# YTM32B1HA0 register map
Vendor: YTMicro; File version: 1.0
CPU: little endian, MPU, FPU, 2 interrupt priority bits
Registers are 32-bit, read-write, reset 0x0 unless marked. A register's access mark holds for its fields unless they carry their own. Offsets are from the block's base; [hi:lo] are bit positions; {n}, {i} and the like mark numbered series; 'fields as' and 'values as' point back to an identical list.

## ENET (part 7 of 10) — Ethernet Quality-of-Service
Base 0x401E4000; register names take the prefix ENET_
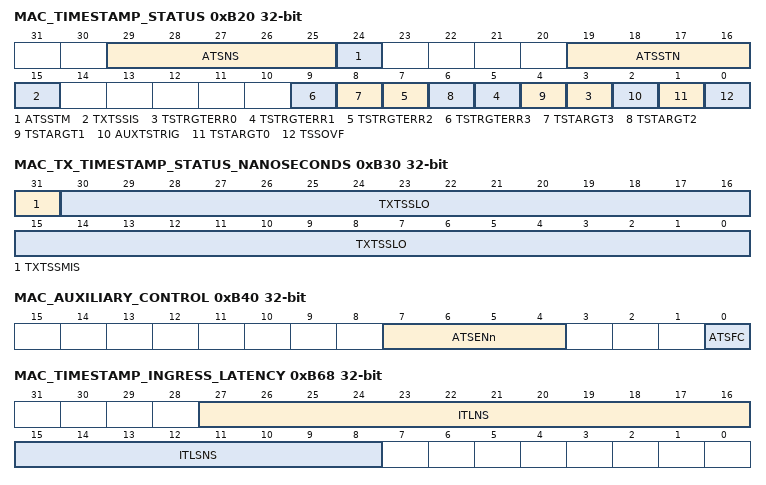
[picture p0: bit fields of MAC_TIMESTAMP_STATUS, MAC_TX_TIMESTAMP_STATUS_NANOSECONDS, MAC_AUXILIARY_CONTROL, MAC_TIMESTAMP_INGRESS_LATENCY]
0xB20 MAC_TIMESTAMP_STATUS ro — Timestamp Status register. All bits except Bits[27:25] gets cleared when the application reads this register.
  [29:25] ATSNS rw — This field indicates the number of Snapshots available in the FIFO. A value equal to the selected depth of FIFO (4, 8, or 16) indicates that the Auxiliary Snapshot FIFO is full. These bits are cleared (to 00000) when the Auxiliary snapshot FIFO clear bit is set. This bit is valid only if the Add IEEE 1588 Auxiliary Snapshot option is selected.
  [24] ATSSTM rw — This bit is set when the Auxiliary timestamp snapshot FIFO is full and external trigger was set. This indicates that the latest snapshot is not stored in the FIFO. This bit is valid only if the Add IEEE 1588 Auxiliary Snapshot option is selected.
    0=Auxiliary Timestamp Snapshot Trigger Missed status not detected; 1=Auxiliary Timestamp Snapshot Trigger Missed status detected
  [19:16] ATSSTN rw — These bits identify the Auxiliary trigger inputs for which the timestamp available in the Auxiliary Snapshot Register is applicable. When more than one bit is set at the same time, it means that corresponding auxiliary triggers were sampled at the same clock. These bits are applicable only if the number of Auxiliary snapshots is more than one. One bit is assigned for each trigger as shown in the following list: ■ Bit 16: Auxiliary trigger 0 ■ Bit 17: Auxiliary trigger 1 ■ Bit 18: Auxiliary trigger 2 ■ Bit 19: Auxiliary trigger 3 The software can read this register to find the triggers that are set when the timestamp is taken. Access restriction applies. Clears on read. Self-set to 1 on internal event.
  [15] TXTSSIS rw — In non-EQOS_CORE configurations when drop transmit status is enabled in MTL, this bit is set when the captured transmit timestamp is updated in the MAC_Tx_Timestamp_Status_Nanoseconds and MAC_Tx_Timestamp_Status_Seconds registers. When PTP offload feature is enabled, this bit is set when the captured transmit timestamp is updated in the MAC_Tx_Timestamp_Status_Nanoseconds and MAC_Tx_Timestamp_Status_Seconds registers, for PTO generated Delay Request and Pdelay request packets. This bit is cleared when the MAC_Tx_Timestamp_Status_Seconds register is read (or write to MAC_Tx_Timestamp_Status_Seconds register when RCWE bit of MAC_CSR_SW_Ctrl register is set).
    0=Tx Timestamp Status Interrupt status not detected; 1=Tx Timestamp Status Interrupt status detected
  [2n+3] TSTRGTERR{n} rw (n=0..3) — This bit is set when the latest target time programmed in the MAC_PPS{n}_Target_Time_Seconds and MAC_PPS{n}_Target_Time_Nanoseconds registers elapses. This bit is cleared when the application reads this bit. Access restriction applies. Clears on read (or this bit is written to 1 when RCWE bit in MAC_CSR_SW_Ctrl register is set). Self-set to 1 on internal event.
    0=Timestamp Target Time Error status not detected; 1=Timestamp Target Time Error status detected
  [8] TSTARGT3 rw — When this bit is set, it indicates that the value of system time is greater than or equal to the value specified in the MAC_PPS3_Target_Time_Seconds and MAC_PPS3_Target_Time_Nanoseconds registers. Access restriction applies. Clears on read (or this bit is written to 1 when RCWE bit in MAC_CSR_SW_Ctrl register is set). Self-set to 1 on internal event.
    0=Timestamp Target Time Reached for Target Time PPS3 status not detected; 1=Timestamp Target Time Reached for Target Time PPS3 status detected
  [6] TSTARGT2 rw — When this bit is set, it indicates that the value of system time is greater than or equal to the value specified in the MAC_PPS2_Target_Time_Seconds and MAC_PPS2_Target_Time_Nanoseconds registers. Access restriction applies. Clears on read (or this bit is written to 1 when RCWE bit in MAC_CSR_SW_Ctrl register is set). Self-set to 1 on internal event.
    0=Timestamp Target Time Reached for Target Time PPS2 status not detected; 1=Timestamp Target Time Reached for Target Time PPS2 status detected
  [4] TSTARGT1 rw — When this bit is set, it indicates that the value of system time is greater than or equal to the value specified in the MAC_PPS1_Target_Time_Seconds and MAC_PPS1_Target_Time_Nanoseconds registers. Access restriction applies. Clears on read (or this bit is written to 1 when RCWE bit in MAC_CSR_SW_Ctrl register is set). Self-set to 1 on internal event.
    0=Timestamp Target Time Reached for Target Time PPS1 status not detected; 1=Timestamp Target Time Reached for Target Time PPS1 status detected
  [2] AUXTSTRIG rw — This bit is set high when the auxiliary snapshot is written to the FIFO. This bit is valid only if the Add IEEE 1588 Auxiliary Snapshot option is selected. Access restriction applies. Clears on read (or this bit is written to 1 when RCWE bit in MAC_CSR_SW_Ctrl register is set). Self-set to 1 on internal event.
    0=Auxiliary Timestamp Trigger Snapshot status not detected; 1=Auxiliary Timestamp Trigger Snapshot status detected
  [1] TSTARGT0 rw — When set, this bit indicates that the value of system time is greater than or equal to the value specified in the MAC_PPS0_Target_Time_Seconds and MAC_PPS0_Target_Time_Nanoseconds registers. Access restriction applies. Clears on read (or this bit is written to 1 when RCWE bit in MAC_CSR_SW_Ctrl register is set). Self-set to 1 on internal event.
    0=Timestamp Target Time Reached status not detected; 1=Timestamp Target Time Reached status detected
  [0] TSSOVF rw — When this bit is set, it indicates that the seconds value of the timestamp (when supporting version 2 format) has overflowed beyond 32'hFFFF_FFFF. Access restriction applies. Clears on read (or this bit is written to 1 when RCWE bit in MAC_CSR_SW_Ctrl register is set). Self-set to 1 on internal event.
    0=Timestamp Seconds Overflow status not detected; 1=Ti
0xB30 MAC_TX_TIMESTAMP_STATUS_NANOSECONDS — This register contains the nanosecond part of timestamp captured for Transmit packets when Tx status is disabled. The MAC_Tx_Timestamp_Status_Nanoseconds register, along with MAC_Tx_Timestamp_Sta- tus_Seconds, gives the 64-bit timestamp captured for the PTP packet successfully transmitted by the MAC. This value is considered to be read by the application when the last byte of MAC_Tx_Time- stamp_Status_Nanoseconds is read. In the little-endian mode, this means when bits[31:24] are read; in big-endian mode, bits[7:0] are read. If the application does not read these registers and timestamp of another packet is captured, then either the current timestamp is lost (overwritten) or the new timestamp is lost (dropped), depending on the setting of the TXTSSTSM bit of the MAC_Timestamp_Control register. The status bit TXTSC bit [15] in MAC_Timestamp_Status register is set whenever the MAC transmitter captures the timestamp.
  [31] TXTSSMIS — When this bit is set, it indicates one of the following: ■ The timestamp of the current packet is ignored if TXTSSTSM bit of the MAC_Timestamp_Control register is reset ■ The timestamp of the previous packet is overwritten with timestamp of the current packet if TXTSSTSM bit of the MAC_Timestamp_Control register is set. Access restriction applies. Clears on read. Self-set to 1 on internal event.
    0=Transmit Timestamp Status Missed status not detected; 1=Transmit Timestamp Status Missed status detected
  [30:0] TXTSSLO — This field contains the 31 bits of the Nanoseconds field of the Transmit packet's captured timestamp.
0xB34 MAC_TX_TIMESTAMP_STATUS_SECONDS — The register contains the higher 32 bits of the timestamp (in seconds) captured when a PTP packet is transmitted.
  [31:0] TXTSSHI — This field contains the lower 32 bits of the Seconds field of Transmit packet's captured timestamp.
0xB40 MAC_AUXILIARY_CONTROL — The Auxiliary Timestamp Control register controls the Auxiliary Timestamp snapshot.
  [7:4] ATSENn — This bit controls the capturing of Auxiliary Snapshot Trigger n. When this bit is set, the auxiliary snapshot of the event on ptp_aux_trig_i[n] input is enabled. When this bit is reset, the events on this input are ignored.
    0=Auxiliary Snapshot n is disabled; 1=Auxiliary Snapshot n is enabled
  [0] ATSFC — When set, this bit resets the pointers of the Auxiliary Snapshot FIFO. This bit is cleared when the pointers are reset and the FIFO is empty. When this bit is high, the auxiliary snapshots are stored in the FIFO. Access restriction applies. Setting 1 sets. Self-cleared. Setting 0 has no effect.
    0=Auxiliary Snapshot FIFO Clear is disabled; 1=Auxiliary Snapshot FIFO Clear is enabled
0xB48 MAC_AUXILIARY_TIMESTAMP_NANOSECONDS — The Auxiliary Timestamp Nanoseconds register, along with MAC_Auxiliary_Time- stamp_Seconds, gives the 64-bit timestamp stored as auxiliary snapshot. These two registers form the read port of a 64-bit wide FIFO with a depth of 4, 8, or 16 as selected while configuring the core. You can store multiple snapshots in this FIFO. Bits[29:25] in MAC_Timestamp_Status indicate the fill-level of the FIFO. The top of the FIFO is removed only when the last byte of MAC_Auxiliary_Time- stamp_Seconds register is read. In the little-endian mode, this means when Bits[31:24] are read and in big-endian mode, Bits[7:0] are read.
  [30:0] AUXTSLO — Contains the lower 31 bits (nanoseconds field) of the auxiliary timestamp.
0xB4C MAC_AUXILIARY_TIMESTAMP_SECONDS — The Auxiliary Timestamp - Seconds register contains the lower 32 bits of the Seconds field of the auxiliary timestamp register.
  [31:0] AUXTSHI — Contains the lower 32 bits of the Seconds field of the auxiliary timestamp.
0xB50 MAC_TIMESTAMP_INGRESS_ASYM_CORR — The MAC Timestamp Ingress Asymmetry Correction register contains the Ingress Asymmetry Correction value to be used while updating correction field in PDelay_Resp PTP messages.
  [31:0] OSTIAC — This field contains the ingress path asymmetry value to be added to correctionField of Pdelay_Resp PTP packet. The programmed value should be in units of nanoseconds and multiplied by 2^16. For example, 2.5 ns is represented as 0x00028000. The value can also be negative, which is represented in 2's complement form with bit 31 representing the sign bit.
0xB54 MAC_TIMESTAMP_EGRESS_ASYM_CORR — The MAC Timestamp Egress Asymmetry Correction register contains the Egress Asym- metry Correction value to be used while updating the correction field in PDelay_Req PTP messages.
  [31:0] OSTEAC — This field contains the egress path asymmetry value to be subtracted from correctionField of Pdelay_Resp PTP packet. The programmed value must be the negated value in units of nanoseconds multiplied by 2^16. For example, if the required correction is +2.5 ns, the programmed value must be 0xFFFD_8000, which is the 2's complement of 0x0002_8000(2.5 * 216). Similarly, if the required correction is -3.3 ns, the programmed value is 0x0003_4CCC (3.3 * 216).
0xB58 MAC_TIMESTAMP_INGRESS_CORR_NANOSECOND — This register contains the correction value in nanoseconds to be used with the captured timestamp value in the ingress path.
  [31:0] TSIC — This field contains the ingress path correction value as defined by the Ingress Correction expression.
0xB5C MAC_TIMESTAMP_EGRESS_CORR_NANOSECOND — This register contains the correction value in nanoseconds to be used with the captured timestamp value in the egress path.
  [31:0] TSEC — This field contains the nanoseconds part of the egress path correction value as defined by the Egress Correction expression.
0xB60 MAC_TIMESTAMP_INGRESS_CORR_SUBNANOSEC — This register contains the sub-nanosecond part of the correction value to be used with the captured timestamp value, for ingress direction.
  [15:8] TSICSNS — This field contains the sub-nanoseconds part of the ingress path correction value as defined by the "Ingress Correction" expression.
0xB64 MAC_TIMESTAMP_EGRESS_CORR_SUBNANOSEC — This register contains the sub-nanosecond part of the correction value to be used with the captured timestamp value, for egress direction.
  [15:8] TSECSNS — This field contains the sub-nanoseconds part of the egress path correction value as defined by the "Egress Correction" expression.
0xB68 MAC_TIMESTAMP_INGRESS_LATENCY ro — This register holds the Ingress MAC latency.
  [27:16] ITLNS rw — This register holds the average latency in sub-nanoseconds between the input ports (phy_rxd_i) of MAC and the actual point (GMII/MII) where the ingress timestamp is taken. Ingress correction value is computed as described in the section 7.1.2.4.1 of QoS Databook.
  [15:8] ITLSNS rw — This register holds the average latency in nanoseconds between the input ports (phy_rxd_i) of MAC and the actual point (GMII/MII) where the ingress timestamp is taken. Ingress correction value is computed as described in the section 7.1.2.4.1 of QoS Databook.
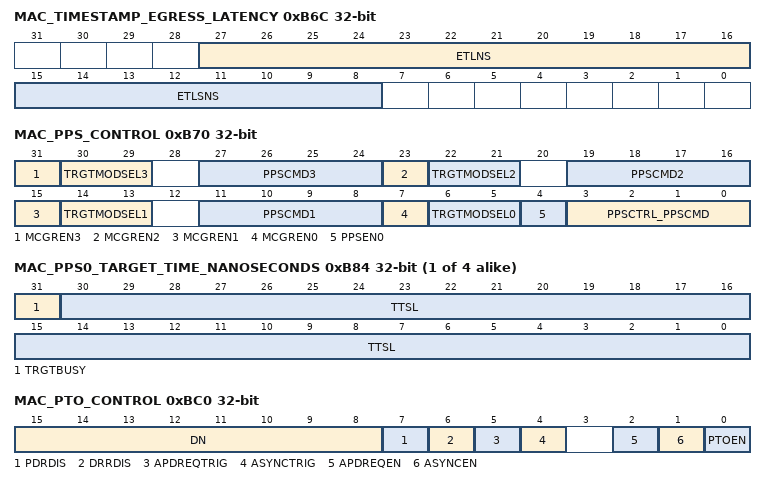
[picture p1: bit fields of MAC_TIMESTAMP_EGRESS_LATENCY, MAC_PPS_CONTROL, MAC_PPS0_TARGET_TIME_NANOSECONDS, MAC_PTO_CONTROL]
0xB6C MAC_TIMESTAMP_EGRESS_LATENCY ro — This register holds the Egress MAC latency.
  [27:16] ETLNS rw — This register holds the average latency in nanoseconds between the actual point (GMII/MII) where the egress timestamp is taken and the output ports (phy_txd_o) of the MAC. Ingress correction value is computed as described in the section 7.1.2.4.2 of QoS Databook.
  [15:8] ETLSNS rw — This register holds the average latency in sub-nanoseconds between the actual point (GMII/MII) where the egress timestamp is taken and the output ports (phy_txd_o) of the MAC. Ingress correction value is computed as described in the section 7.1.2.4.2 of QoS Databook.
0xB70 MAC_PPS_CONTROL — Bits[30:24] of this register are valid only when four Flexible PPS outputs are selected. Bits[22:16] are valid only when three or more Flexible PPS outputs are selected. Bits[14:8] are valid only when two or more Flexible PPS outputs are selected. Bits[6:4] are valid only when Flexible PPS feature is selected.
  [31] MCGREN3 — This field enables the 3rd PPS instance to operate in PPS or MCGR mode. When set it operates in MCGR mode and on reset it operates in PPS mode.
  [8n+6:8n+5] TRGTMODSEL{n} (n=0..3) — This field indicates the Target Time registers (MAC_PPS{n}_Target_Time_Seconds and MAC_PPS{n}_Target_Time_Nanoseconds) mode for PPS{n} output signal.
    0=Target Time registers are programmed only for generating the interrupt event. The Flexible PPS function must not be enabled in this mode, otherwise spurious transitions may be observed on the corre- sponding ptp_pps_o output port; 2=Target Time registers are programmed for generating the interrupt event and starting or stopping the PPS0 output signal generation; 3=Target Time registers are programmed only for starting or stopping the PPS0 output signal gener- ation. No interrupt is asserted
  [27:24] PPSCMD3 — This field controls the flexible PPS3 output (ptp_pps_o[3]) signal. This field is similar to the PPSCMD0[2:0] field. If MCGREN3 is set, then PPSCMD3 indicated by these 4 bits [27:24] are taken as Presentation Time Control bits for media clock generation and recovery for comparator instance 3. This field is similar to the PPSCMD0 Presentation Time Control bits. If MCGREN3 is not set then only 3 bits from [26:24] is used as PPSCMD3 and the 4th bit is to be set as 0. Access restriction applies. Setting 1 sets. Self-cleared. Setting 0 has no effect.
  [23] MCGREN2 — This field enables the 2nd PPS instance to operate in PPS or MCGR mode. When set it operates in MCGR mode and on reset it operates in PPS mode.
    0=2nd PPS instance is disabled to operate in PPS or MCGR mode; 1=2nd PPS instance is enabled to operate in PPS or MCGR mode
  [19:16] PPSCMD2 — This field controls the flexible PPS2 output (ptp_pps_o[2]) signal. This field is similar to the PPSCMD0[2:0] field. If MCGREN2 is set, then PPSCMD2 indicated by these 4 bits [19:16] are taken as Presentation Time Control bits for media clock generation and recovery for comparator instance 2. This field is similar to the PPSCMD0 Presentation Time Control bits. If MCGREN2 is not set then only 3 bits from [18:16] is used as PPSCMD2 and the 4th bit is to be set as 0. Access restriction applies. Setting 1 sets. Self-cleared. Setting 0 has no effect.
  [15] MCGREN1 — This field enables the 1st PPS instance to operate in PPS or MCGR mode. When set it operates in MCGR mode and on reset it operates in PPS mode.
    0=1st PPS instance is disabled to operate in PPS or MCGR mode; 1=1st PPS instance is enabled to operate in PPS or MCGR mode
  [11:8] PPSCMD1 — This field controls the flexible PPS1 output (ptp_pps_o[1]) signal. This field is similar to the PPSCMD0[2:0] field. If MCGREN1 is set, then PPSCMD1 indicated by these 4 bits [11:8] are taken as Presentation Time Control bits for media clock generation and recovery for comparator instance 1. This field is similar to the PPSCMD0 Presentation Time Control bits. If MCGREN1 is not set then only 3 bits from [10:8] is used as PPSCMD1 and the 4th bit is to be set as 0. Access restriction applies. Setting 1 sets. Self-cleared. Setting 0 has no effect.
  [7] MCGREN0 — This field enables the 0th PPS instance to operate in PPS or MCGR mode. When set it operates in MCGR mode and on reset it operates in PPS mode.
    0=0th PPS instance is disabled to operate in PPS or MCGR mode; 1=0th PPS instance is enabled to operate in PPS or MCGR mode
  [4] PPSEN0 — When this bit is set, Bits[3:0] function as PPSCMD. When this bit is reset, Bits[3:0] function as PPSCTRL (Fixed PPS mode).
    0=Flexible PPS Output Mode is disabled; 1=Flexible PPS Output Mode is enabled
  [3:0] PPSCTRL_PPSCMD — // TODO This field controls the frequency of the PPS0 output (ptp_pps_o[0]) signal. The default value of PPSCTRL is 0000, and the PPS output is 1 pulse (of width clk_ptp_i) every second. For other values of PPSCTRL, the PPS output becomes a generated clock of following frequencies: ■ 0001: The binary rollover is 2 Hz, and the digital rollover is 1 Hz. ■ 0010: The binary rollover is 4 Hz, and the digital rollover is 2 Hz. ■ 0011: The binary rollover is 8 Hz, and the digital rollover is 4 Hz. ■ 0100: The binary rollover is 16 Hz, and the digital rollover is 8 Hz. ■ .. ■ 1111: The binary rollover is 32.768 KHz and the digital roll- over is 16.384 KHz. Note: In the binary rollover mode, the PPS output (ptp_pps_o) has a duty cycle of 50 percent with these frequencies. In the digital rollover mode, the PPS output frequency is an average number. The actual clock is of different frequency that gets synchronized every second. For example: ■ When PPSCTRL = 0001, the PPS (1 Hz) has a low period of 537 ms and a high period of 463 ms ■ When PPSCTRL = 0010, the PPS (2 Hz) is a sequence of One clock of 50 percent duty cycle and 537 ms period Second clock of 463 ms period (268 ms low and 195 ms high) ■ When PPSCTRL = 0011, the PPS (4 Hz) is a sequence of Three clocks of 50 percent duty cycle and 268 ms period Fourth clock of 195 ms period (134 ms low and 61 ms high) This behavior is because of the non-linear toggling of bits in the digital rollover mode in the MAC_System_Time_Nanoseconds register. or Flexible PPS Output (ptp_pps_o[0]) Control Programming these bits with a non-zero value instructs the MAC to initiate an event. When the command is transferred or synchronized to the PTP clock domain, these bits get cleared automatically. The software should ensure that these bits are programmed only when they are 'all-zero'. The following list describes the values of PPSCMD0: ■ 0000: No Command ■ 0001: START Single Pulse This command generates single pulse rising at the start point defined in MAC_PPS0_Target_Time_Seconds and MAC_PPS0_Target_Time_Nanoseconds register and of a duration defined in the PPS0 Width Register. ■ 0010: START Pulse Train This command generates the train of pulses rising at the start point defined in the Target Time Registers and of a duration defined in the PPS0 Width Register and repeated at interval defined in the PPS Interval Register. By default, the PPS pulse train is free-running unless stopped by the 'Stop Pulse train at time' or 'Stop Pulse Train immediately' commands. ■ 0011: Cancel START This command cancels the START Single Pulse and START Pulse Train commands if the system time has not crossed the programmed start time. ■ 0100: STOP Pulse train at time This command stops the train of pulses initiated by the START Pulse Train command (PPSCMD = 0010) after the time programmed in the Target Time registers elapses. ■ 0101: STOP Pulse Train immediately This command immediately stops the train of pulses initiated by the START Pulse Train command (PPSCMD = 0010). ■ 110: Cancel STOP Pulse train This command cancels the STOP pulse train at time command if the programmed stop time has not elapsed. The PPS pulse train becomes free-running on the successful execution of this command. ■ 0111-1111: Reserved or Presentation Time Control If MCGREN0 is set then these bits are treated as Presentation time control bits. The following list describes the values of PPSCMD0: ■ 0000: No Operation related to MCGR will be carried out. If set to this value in the mid of clock recovery or generation all the processing inputs will be flushed. ■ 0001: Capture the Presentation time at rising edge of mcg_pst_trig_i[0] into the MAC_PPS0_Target_Time_Sec- onds register ■ 0010: Capture the Presentation time at falling edge of mcg_pst_trig_i[0] into the MAC_PPS0_Target_Time_Sec- onds register ■ 0011: Capture the Presentation time at both edges of mcg_pst_trig_i[0] into the MAC_PPS0_Target_Time_Sec- onds register ■ 0100-1000: Reserved ■ 1001: Toggle output on compare ■ 1010: Pulse output low on compare for one PTP-clock cycle ■ 1011: Pulse output high on compare for one PTP-clock cycle ■ 1100-1111: Reserved
{0xB80+0x10*i} MAC_PPS{i}_TARGET_TIME_SECONDS (i=0..3) — The PPS Target Time Seconds register, along with PPS Target Time Nanoseconds register, is used to schedule an interrupt event [Bit 1 of MAC_Timestamp_Status] when the system time exceeds the value programmed in these registers.
  [31:0] TSTRH — This field stores the time in seconds. When the timestamp value matches or exceeds both Target Timestamp registers, the MAC starts or stops the PPS signal output and generates an interrupt (if enabled) based on Target Time mode selected for the corresponding PPS output in the MAC_PPS_Control register. If DWC_EQOS_FLEXI_PPS_OUT_EN is enabled in the configuration and PTGE field of MAC_Timestamp_Control Register is set with Presentation time control set in recovery mode, then these bits indicate the TPT being programmed by the application and in generation mode it indicates the CPT generated at the sampled trigger.
{0xB84+0x10*i} MAC_PPS{i}_TARGET_TIME_NANOSECONDS (i=0..3) — PPSn Target Time Nanoseconds register.
  [31] TRGTBUSY — The MAC sets this bit when the PPSCMDn field in the MAC_PPS_Control register is programmed to 010 or 011. Programming the PPSCMDn field to 010 or 011 instructs the MAC to synchronize the Target Time Registers to the PTP clock domain. The MAC clears this bit after synchronizing the Target Time Registers to the PTP clock domain The application must not update the Target Time Registers when this bit is read as 1. Otherwise, the synchronization of the previous programmed time gets corrupted.
    0=PPS Target Time Register Busy status is not detected; 1=PPS Target Time Register Busy is detected
  [30:0] TTSL — This register stores the time in (signed) nanoseconds. When the value of the timestamp matches the value in both Target Timestamp registers, the MAC starts or stops the PPS signal output and generates an interrupt (if enabled) based on the TRGTMODSEL0 field (Bits [6:5]) in MAC_PPS_Control. When the TSCTRLSSR bit is reset in the MAC_Timestamp_Control register, this value should be (time in ns / 0.465). The actual start or stop time of the PPS signal output may have an error margin up to one unit of sub-second increment value. When the TSCTRLSSR bit is set in the MAC_Timestamp_Control register, this value should not exceed 0x3B9A_C9FF. The actual start or stop time of the PPS signal output may have an error margin up to one unit of sub-second increment value. Access restriction applies. Setting 1 sets. Self-cleared. Setting 0 has no effect.
{0xB88+0x10*i} MAC_PPS{i}_INTERVAL (i=0..3) — The PPSn Interval register contains the number of units of sub-second increment value between the rising edges of PPSn signal output (ptp_pps_o[n]).
  [31:0] PPSINT — These bits store the interval between the rising edges of PPS0 signal output. The interval is stored in terms of number of units of sub-second increment value. You need to program one value less than the required interval. For example, if the PTP reference clock is 50 MHz (period of 20 ns), and desired interval between the rising edges of PPS0 signal output is 100 ns (that is, 5 units of sub-second increment value), you should program value 4 (5-1) in this register.
{0xB8C+0x10*i} MAC_PPS{i}_WIDTH (i=0..3) — The PPSn Width register contains the number of units of sub-second increment value between the rising and corresponding falling edges of PPSn signal output (ptp_pps_o[n]).
  [31:0] PPSWIDTH — These bits store the width between the rising edge and corresponding falling edge of PPSn signal output. The width is stored in terms of number of units of sub-second increment value. You need to program one value less than the required interval. For example, if PTP reference clock is 50 MHz (period of 20 ns), and width between the rising and corresponding falling edges of PPSn signal output is 80 ns (that is, four units of sub-second increment value), you should program value 3 (4-1) in this register. Note: The value programmed in this register must be lesser than the value programmed in MAC_PPSn_Interval.
0xBC0 MAC_PTO_CONTROL — This register controls the PTP Offload Engine operation. This register is available only when the Enable PTP Timestamp Offload feature is selected.
  [15:8] DN — This field indicates the domain Number in which the PTP node is operating.
  [7] PDRDIS — When this bit is set, the Peer Delay Response (Pdelay_Resp) response is not be generated for received Peer Delay Request (Pdelay_Req) request packet, as required by the programmed mode. Note: Setting this bit to 1 affects the normal PTP Offload operation and the time synchronization. So, this bit must be set only if there is problem with Pdelay_Resp generation in Hardware and/or Pdelay_Resp generation is handled by Software.
    0=Peer Delay Response response generation is enabled; 1=Peer Delay Response response generation is disabled
  [6] DRRDIS — When this bit is set, the Delay Request and Delay response is not generated for received SYNC and Delay request packet respectively, as required by the programmed mode.
    0=PTO Delay Request/Response response generation is enabled; 1=PTO Delay Request/Response response generation is disabled
  [5] APDREQTRIG — When this bit is set, one PTP Pdelay_Req message is transmitted. This bit is automatically cleared after the PTP Pdelay_Req message is transmitted. The application should set the APDREQEN bit for this operation. Access restriction applies. Setting 1 sets. Self-cleared. Setting 0 has no effect.
    0=Automatic PTP Pdelay_Req message Trigger is disabled; 1=Automatic PTP Pdelay_Req message Trigger is enabled
  [4] ASYNCTRIG — When this bit is set, one PTP SYNC message is transmitted. This bit is automatically cleared after the PTP SYNC message is transmitted. The application should set the ASYNCEN bit for this operation. Access restriction applies. Setting 1 sets. Self-cleared. Setting 0 has no effect.
    0=Automatic PTP SYNC message Trigger is disabled; 1=Automatic PTP SYNC message Trigger is enabled
  [2] APDREQEN — When this bit is set, PTP Pdelay_Req message is generated periodically based on interval programmed or trigger from application, when the MAC is programmed to be in Peer-to-Peer Transparent mode.
    0=Automatic PTP Pdelay_Req message is disabled; 1=Automatic PTP Pdelay_Req message is enabled
  [1] ASYNCEN — When this bit is set, PTP SYNC message is generated periodically based on interval programmed or trigger from application, when the MAC is programmed to be in Clock Master mode.
    0=Automatic PTP SYNC message is disabled; 1=Automatic PTP SYNC message is enabled
  [0] PTOEN — When this bit is set, the PTP Offload feature is enabled.
    0=PTP Offload feature is disabled; 1=PTP Offload feature is enabled
0xBC4 MAC_SOURCE_PORT_IDENTITY — This register contains Bits[31:0] of the 80-bit Source Port Identity of the PTP node. This register is available only when the Enable PTP Timestamp Offload feature is selected.
  [31:0] SPI — This field indicates bits [31:0] of sourcePortIdentity of PTP node.
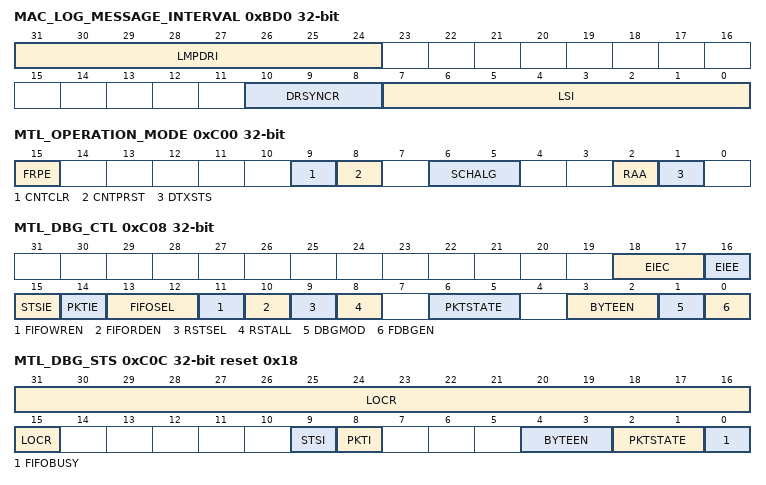
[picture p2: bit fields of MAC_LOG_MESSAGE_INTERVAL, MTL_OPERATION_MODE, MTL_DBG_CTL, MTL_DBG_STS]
0xBD0 MAC_LOG_MESSAGE_INTERVAL — This register contains the periodic intervals for automatic PTP packet generation. This register is available only when the Enable PTP Timestamp Offload feature is selected.
  [31:24] LMPDRI — This field indicates logMinPdelayReqInterval of PTP node. This is used to schedule the periodic Pdelay request packet transmission. Allowed values are -15 to 15.Negative value must be represented in 2's-complement form. For example, if the required value is -1, the value programmed must be 0xFF.
  [10:8] DRSYNCR — In Slave mode, it is used for controlling frequency of Delay_Req messages transmitted. ■ 0: DelayReq generated for every received SYNC ■ 1: DelayReq generated every alternate reception of SYNC ■ 2: for every 4 SYNC messages ■ 3: for every 8 SYNC messages ■ 4: for every 16 SYNC messages ■ 5: for every 32 SYNC messages ■ 6-7: Reserved The master sends this information (logMinDelayReqInterval) in the DelayResp PTP messages to the slave. The DWC_ether_qos Receiver processes this value from the received DelayResp messages and updates this field accordingly. In the Slave mode, the host must not write/update this register unless it has to override the received value. In Master mode, the sum of this field and logSyncInterval (LSI) field is provided in the logMinDelayReqInterval field of the generated multicast Delay_Resp PTP message. Access restriction applies. Updated based on the event. Setting 1 sets. Setting 0 clears.
    0=DelayReq generated for every received SYNC; 1=DelayReq generated every alternate reception of SYNC; 2=for every 4 SYNC messages; 3=for every 8 SYNC messages; 4=for every 16 SYNC messages; 5=for every 32 SYNC messages
  [7:0] LSI — This field indicates the periodicity of the automatically generated SYNC message when the PTP node is Master. Allowed values are -15 to 15. Negative value must be represented in 2's-complement form. For example, if the required value is -1, the value programmed must be 0xFF.
0xC00 MTL_OPERATION_MODE
  [15] FRPE — When this bit is set to 1, the Programmable Rx Parser functionality is enabled. When the Rx parser is disabled and if the Rx parser is in the middle of the parsing then it gets disabled only after completing the current packet parsing. When the Rx parser is enabled from disabled state then the Rx parser gets activated for the next immediate packet.
    0=Flexible Rx parser is disabled; 1=Flexible Rx parser is enabled
  [9] CNTCLR — When this bit is set, all counters are reset. This bit is cleared automatically after 1 clock cycle. If this bit is set along with CNT_PRESET bit, CNT_PRESET has precedence. Access restriction applies. Setting 1 sets. Self-cleared. Setting 0 has no effect.
    0=Counters are not reset; 1=Counters are reset
  [8] CNTPRST — When this bit is set, ■ MTL_TxQ[0-7]_Underflow register is initialized/preset to 12'h7F0. ■ Missed Packet and Overflow Packet counters in MTL_RxQ[0-7]_Missed_Packet_Overflow_Cnt register is initialized/preset to 12'h7F0. Access restriction applies. Setting 1 sets. Self-cleared. Setting 0 has no effect.
    0=Counters Preset is disabled; 1=Counters Preset is enabled
  [6:5] SCHALG — This field indicates the algorithm for Tx scheduling:
    0=WRR algorithm; 1=WFQ algorithm when DCB feature is selected.Otherwise, Reserved; 2=DWRR algorithm when DCB feature is selected.Otherwise, Reserved; 3=Strict priority algorithm
  [2] RAA — This field is used to select the arbitration algorithm for the Rx side. ■ 0: Strict priority (SP) Queue 0 has the lowest priority and the last queue has the highest priority. ■ 1: Weighted Strict Priority (WSP)
    0=Strict priority (SP); 1=Weighted Strict Priority (WSP)
  [1] DTXSTS — When this bit is set, the Tx packet status received from the MAC is dropped in the MTL. When this bit is reset, the Tx packet status received from the MAC is forwarded to the application.
    0=Drop Transmit Status is disabled; 1=Drop Transmit Status is enabled
0xC08 MTL_DBG_CTL — The FIFO Debug Access Control and Status register controls the operation mode of FIFO debug access.
  [18:17] EIEC — When EIEE bit of this register is set, following are the errors inserted based on the value encoded in this field.
    0=Insert 1 bit error; 1=Insert 2 bit error; 2=Insert 3 bit error; 3=Insert 1 bit error in address field
  [16] EIEE — When set, enables the ECC error injection feature. When reset, disables the ECC error injection feature.
    0=ECC Inject Error for Tx, Rx and TSO memories is disabled; 1=ECC Inject Error for Tx, Rx and TSO memories is enabled
  [15] STSIE — When this bit is set, an interrupt is generated when Transmit status is available in slave mode.
    0=Transmit Packet Available Interrupt Status is disabled; 1=Transmit Packet Available Interrupt Status is enabled
  [14] PKTIE — When this bit is set, an interrupt is generated when EOP of received packet is written to the Rx FIFO.
    0=Receive Packet Available Interrupt Status is disabled; 1=Receive Packet Available Interrupt Status is enabled
  [13:12] FIFOSEL — This field indicates the FIFO selected for debug access:
    0=Tx FIFO; 1=Tx Status FIFO (only read access when SLVMOD is set); 2=TSO FIFO (cannot be accessed when SLVMOD is set); 3=Rx FIFO
  [11] FIFOWREN — When this bit is set, it enables the Write operation on selected FIFO when FIFO Debug Access is enabled. This bit must not be written to 1 when FIFO Debug Access is not enabled, that is FDBGEN bit is 0. Access restriction applies. Self-cleared. Setting 0 clears. Setting 1 sets.
    0=FIFO Write is disabled; 1=FIFO Write is enabled
  [10] FIFORDEN — When this bit is set, it enables the Read operation on selected FIFO when FIFO Debug Access is enabled. This bit must not be written to 1 when FIFO Debug Access is not enabled, that is FDBGEN bit is 0. Access restriction applies. Self-cleared. Setting 0 clears. Setting 1 sets.
    0=FIFO Read is disabled; 1=FIFO Read is enabled
  [9] RSTSEL — When this bit is set, the pointers of the currently-selected FIFO are reset when FIFO Debug Access is enabled. This bit must not be written to 1 when FIFO Debug Access is not enabled, that is FDBGEN bit is 0. Access restriction applies. Self-cleared. Setting 0 clears. Setting 1 sets.
    0=Reset Pointers of Selected FIFO is disabled; 1=Reset Pointers of Selected FIFO is enabled
  [8] RSTALL — When this bit is set, the pointers of all FIFOs are reset when FIFO Debug Access is enabled. This bit must not be written to 1 when FIFO Debug Access is not enabled, that is FDBGEN bit is 0. Access restriction applies. Self-cleared. Setting 0 clears. Setting 1 sets.
    0=Reset All Pointers is disabled; 1=Reset All Pointers is enabled
  [6:5] PKTSTATE — This field is used to write the control information to the Tx FIFO or Rx FIFO. Tx FIFO: ■ 00: Packet Data ■ 01: Control Word ■ 10: SOP Data ■ 11: EOP Data Rx FIFO: ■ 00: Packet Data ■ 01: Normal Status ■ 10: Last Status ■ 11: EOP
    0=Packet Data; 1=Control Word/Normal Status; 2=SOP Data/Last Status; 3=EOP Data/EOP
  [3:2] BYTEEN — This field indicates the number of data bytes valid in the data register during Write operation. This is valid only when PKTSTATE is 2'b10 (EOP) and Tx FIFO or Rx FIFO is selected.
    0=Byte 0 valid; 1=Byte 0 and Byte 1 are valid; 2=Byte 0, Byte 1 and Byte 2 are valid; 3=All four bytes are valid
  [1] DBGMOD — When this bit is set, it indicates that the current access to the FIFO is read, write, and debug access. In this mode, the following access types are allowed: ■ Read and Write access to Tx FIFO, TSO FIFO, and Rx FIFO ■ Read access is allowed to Tx Status FIFO. When this bit is reset, it indicates that the current access to the FIFO is slave access bypassing the DMA. In this mode, the following access are allowed: ■ Write access to the Tx FIFO ■ Read access to the Rx FIFO and Tx Status FIFO
    0=Debug Mode Access to FIFO is disabled; 1=Debug Mode Access to FIFO is enabled
  [0] FDBGEN — When this bit is set, it indicates that the debug mode access to the FIFO is enabled. When this bit is reset, it indicates that the FIFO can be accessed only through a master interface.
    0=FIFO Debug Access is disabled; 1=FIFO Debug Access is enabled
0xC0C MTL_DBG_STS ro reset 0x18 — The FIFO Debug Status register contains the status of FIFO debug access.
  [31:15] LOCR rw — Slave Access Mode: This field indicates the space available in selected FIFO. Debug Access Mode: This field contains the Write or Read pointer value of the selected FIFO during Write or Read operation, respectively. Reset: In single Tx Queue configurations, (DWC_EQOS_TXFIFO_SIZE/(DWC_EQOS_DATAWIDTH/8)), Otherwise 0000H
  [9] STSI rw — When set, this bit indicates that the Slave mode Tx packet is transmitted, and the status is available in Tx Status FIFO. This bit is reset when 1 is written to this bit.
    0=Transmit Status Available Interrupt Status not detected; 1=Transmit Status Available Interrupt Status detected
  [8] PKTI rw — When set, this bit indicates that MAC layer has written the EOP of received packet to the Rx FIFO. This bit is reset when 1 is written to this bit.
    0=Receive Packet Available Interrupt Status not detected; 1=Receive Packet Available Interrupt Status detected
  [4:3] BYTEEN rw — This field indicates the number of data bytes valid in the data register during Read operation. This is valid only when PKTSTATE is 2'b10 (EOP) and Tx FIFO or Rx FIFO is selected.
    values as MTL_DBG_CTL.BYTEEN
  [2:1] PKTSTATE rw — This field is used to get the control or status information of the selected FIFO. Tx FIFO: ■ 00: Packet Data ■ 01: Control Word ■ 10: SOP Data ■ 11: EOP Data Rx FIFO: ■ 00: Packet Data ■ 01: Normal Status ■ 10: Last Status ■ 11: EOP This field is applicable only for Tx FIFO and Rx FIFO during Read operation.
    values as MTL_DBG_CTL.PKTSTATE
  [0] FIFOBUSY rw — When set, this bit indicates that a FIFO operation is in progress in the MAC and content of the following fields is not valid: ■ All other fields of this register ■ All fields of the MTL_FIFO_Debug_Data register
    0=FIFO Busy not detected; 1=FIFO Busy detected
0xC10 MTL_DBG_DATA ro — The FIFO Debug Data register contains the data to be written to or read from the FIFOs.
  [31:0] FDBGDATA rw — During debug or slave access write operation, this field contains the data to be written to the Tx FIFO, Rx FIFO, or TSO FIFO. During debug or slave access read operation, this field contains the data read from the Tx FIFO, Rx FIFO, TSO FIFO, or Tx Status FIFO.
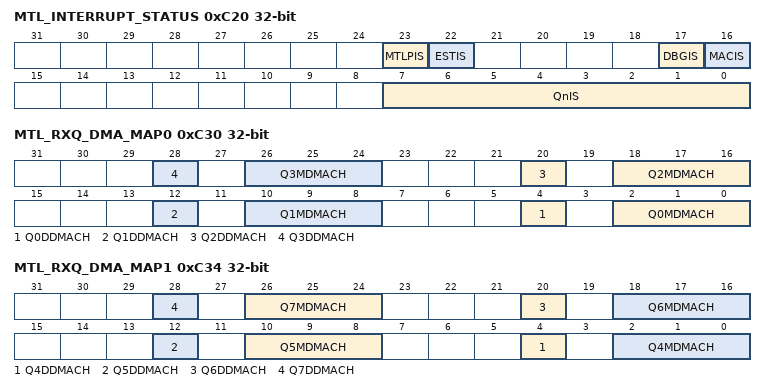
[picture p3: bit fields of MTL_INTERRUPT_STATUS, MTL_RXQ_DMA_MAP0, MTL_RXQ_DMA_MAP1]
0xC20 MTL_INTERRUPT_STATUS ro — The software driver (application) reads this register during interrupt service routine or polling to determine the interrupt status of MTL queues and the MAC.
  [23] MTLPIS rw — This bit indicates that there is an interrupt from Rx Parser Block. To reset this bit, the application must read the MTL_ Rxp_Interrupt_Status register to get the exact cause of the interrupt and clear its source.
    0=MTL Rx Parser Interrupt status not detected; 1=MTL Rx Parser Interrupt status detected
  [22] ESTIS rw — This bit indicates an interrupt event during the operation of 802.1Qbv. To reset this bit, the application must clear the error/event that has caused the Interrupt.
    0=EST (TAS- 802.1Qbv) Interrupt status not detected; 1=EST (TAS- 802.1Qbv) Interrupt status detected
  [17] DBGIS rw — This bit indicates an interrupt event during the slave access. To reset this bit, the application must read the FIFO Debug Access Status register to get the exact cause of the interrupt and clear its source.
    0=Debug Interrupt status not detected; 1=Debug Interrupt status detected
  [16] MACIS rw — This bit indicates an interrupt event from the MAC. To reset this bit, the application must read the MAC Interrupt Status register to get the exact cause of the interrupt and clear its source.
    0=MAC Interrupt status not detected; 1=MAC Interrupt status detected
  [7:0] QnIS rw — This bit indicates that there is an interrupt from Queue n. To reset this bit, the application must read the MTL_Qn_Interrupt_Control_Status Status register to get the exact cause of the interrupt and clear its source. One bit for one queue.
0xC30 MTL_RXQ_DMA_MAP0 — The Receive Queue and DMA Channel Mapping 0 register is reserved in EQOS-CORE and EQOS-MTL configurations.
  [8n+4] Q{n}DDMACH (n=0..3) — When set, this bit indicates that the packets received in Queue {n} are routed to a particular DMA channel as decided in the MAC Receiver based on the DMA channel number programmed in the L3-L4 filter registers, or the Ethernet DA address. When reset, this bit indicates that the packets received in Queue {n} are routed to the DMA Channel programmed in the Q{n}MDMACH field (Bits[{8n+2}:{8n}]).
    0=Queue {n} disabled for DA-based DMA Channel Selection; 1=Queue {n} enabled for DA-based DMA Channel Selection
  [8n+2:8n] Q{n}MDMACH (n=0..3) — This field controls the routing of the received packet in Queue {n} to the DMA Channel. This field is valid when the Q{n}DDMACH field is reset. Note: The width of this field depends on the number of RX DMA channels and not all the values may be valid in some configurations. For example, if the number of RX DMA channels selected is 2, only 000 and 001 are valid, the others are reserved
    {v}=DMA Channel {v} (v=0..7)
0xC34 MTL_RXQ_DMA_MAP1 — The Receive Queue and DMA Channel Mapping 1 register is reserved in EQOS-CORE and EQOS-MTL configurations.
  [8n-28] Q{n}DDMACH (n=4..7) — When set, this bit indicates that the packets received in Queue {n} are routed to a particular DMA channel as decided in the MAC Receiver based on the DMA channel number programmed in the L3-L4 filter registers, or the Ethernet DA address. When reset, this bit indicates that the packets received in Queue {n} are routed to the DMA Channel programmed in the Q{n}MDMACH field (Bits[{8n-30}:{8n-32}]).
    values as MTL_RXQ_DMA_MAP0.Q0DDMACH
  [26:24] Q7MDMACH — This field controls the routing of the received packet in Queue 7 to the DMA Channel. This field is valid when the Q7DDMACH field is reset. Note: The width of this field depends on the number of RX DMA channels and not
  [18:16] Q6MDMACH — This field controls the routing of the received packet in Queue 6 to the DMA Channel. This field is valid when the Q6DDMACH field is reset. Note: The width of this field depends on the number of RX DMA channels and not all the values may be valid in some configurations. For example, if the number of RX DMA channels selected is 2, only 000 and 001 are valid, the others are reserved
    {v}=DMA Channel {v} (v=0..7)
  [10:8] Q5MDMACH — This field controls the routing of the received packet in Queue 5 to the DMA Channel. This field is valid when the Q5DDMACH field is reset. Note: The width of this field depends on the number of RX DMA channels and not all the values may be valid in some configurations. For example, if the number of RX DMA channels selected is 2, only 000 and 001 are valid, the others are reserved
    {v}=DMA Channel {v} (v=0..7)
  [2:0] Q4MDMACH — This field controls the routing of the received packet in Queue 4 to the DMA Channel. This field is valid when the Q4DDMACH field is reset. Note: The width of this field depends on the number of RX DMA channels and not all the values may be valid in some configurations. For example, if the number of RX DMA channels selected is 2, only 000 and 001 are valid, the others are reserved
    {v}=DMA Channel {v} (v=0..7)
